# ADSP-2183xW_LPC register map
Vendor: Analog Devices; Series: ADSP-2183xW_LPC; File version: 3.0.3.517
CPU: 
Registers are 32-bit, read-write, reset 0x0 unless marked. A register's access mark holds for its fields unless they carry their own. Offsets are from the block's base; [hi:lo] are bit positions; 'fields as' and 'values as' point back to an identical list.

## DMC0_PHY — 1600MHz DMCPHY (DDR3/DDR3L)
Base 0x31071000
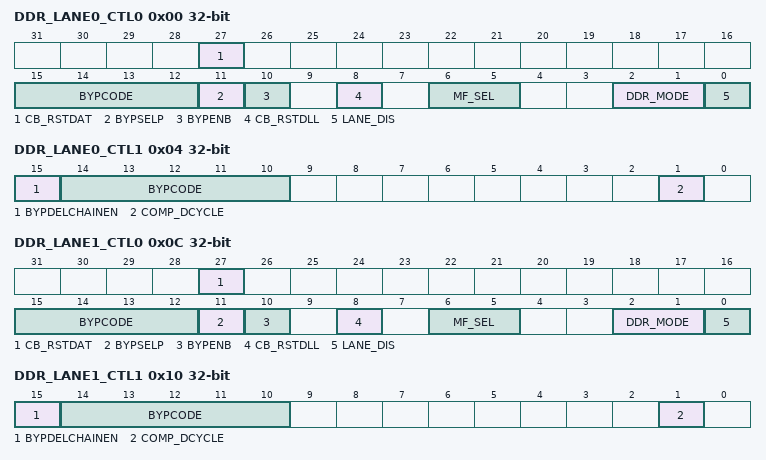
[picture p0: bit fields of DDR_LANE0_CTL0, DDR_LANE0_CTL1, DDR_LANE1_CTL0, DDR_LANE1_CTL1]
0x00 DDR_LANE0_CTL0 — Data Lane 0 Control Register 0
  [27] CB_RSTDAT range 0x00000000..0x00000001 — Reset the Data Pads
  [15:12] BYPCODE range 0x00000000..0x0000000F — Duty Cycle Level
  [11] BYPSELP — Duty Cycle Offset Direction Select
    0=Direction_neg (Negative); 1=Direction_pos (Positive)
  [10] BYPENB — DQS Duty Cycle Offset Adjustment Enable
    0=DQS_Duty_disable (Disable); 1=DQS_duty_enable (Enable)
  [8] CB_RSTDLL range 0x00000000..0x00000001 — Reset the Lane DLL
  [6:5] MF_SEL — SPI Master Frequency Divider Select
    0=DIVBY2 (Divide by 2); 1=DIVBY4 (Divide by 4); 2=DIVBY8 (Divide by 8); 3=DIVBY16 (Divide by 16)
  [2:1] DDR_MODE
    0=DDR3 (DDR3/3L Mode)
  [0] LANE_DIS — Clock Gate Data Lane
    0=ENABLED (Lane is Enabled); 1=DISABLED (Lane is Clock Gated)
0x04 DDR_LANE0_CTL1 — Data Lane 0 Control Register 1
  [15] BYPDELCHAINEN range 0x00000000..0x00000001 — Bypass enable for delay chain controlling extra delay on DATA pins
  [14:10] BYPCODE range 0x00000000..0x0000001F — Bypass Code for extra delay on DATA pins
  [1] COMP_DCYCLE range 0x00000000..0x00000001 — Compute Datacycle
0x0C DDR_LANE1_CTL0 — Data Lane 1 Control Register 0
  fields as DDR_LANE0_CTL0
0x10 DDR_LANE1_CTL1 — Data Lane 1 Control Register 1
  fields as DDR_LANE0_CTL1
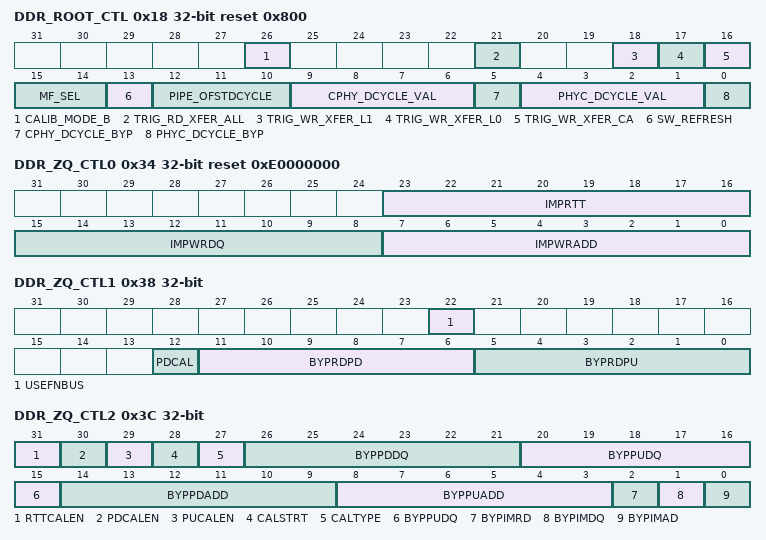
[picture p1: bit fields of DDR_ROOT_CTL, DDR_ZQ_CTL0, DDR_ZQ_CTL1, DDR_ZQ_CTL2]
0x18 DDR_ROOT_CTL reset 0x800 — DDR ROOT Module Control Register
  [26] CALIB_MODE_B range 0x00000000..0x00000001 — Select control bits for CA lane from scratch registers instead of ZQ_CTL registers
  [21] TRIG_RD_XFER_ALL range 0x00000000..0x00000001 — All Lane Read Status
  [18] TRIG_WR_XFER_L1 range 0x00000000..0x00000001 — Write Transfer from Root to Lane1
  [17] TRIG_WR_XFER_L0 range 0x00000000..0x00000001 — Write Transfer from Root to Lane 0
  [16] TRIG_WR_XFER_CA range 0x00000000..0x00000001 — Write Transfer from Root to CA Lane
  [15:14] MF_SEL — SPI Master Frequency Divider Select
    values as DDR_LANE0_CTL0.MF_SEL
  [13] SW_REFRESH range 0x00000000..0x00000001 — Refresh Lane DLL Code
  [12:10] PIPE_OFSTDCYCLE range 0x00000000..0x00000007 — Pipeline offset for PHYC_DATACYCLE
  [9:6] CPHY_DCYCLE_VAL range 0x00000000..0x0000000F — Bypass Value for CPHY_DATACYCLE
  [5] CPHY_DCYCLE_BYP range 0x00000000..0x00000001 — Bypass Enable for CPHY_DATACYCLE
  [4:1] PHYC_DCYCLE_VAL range 0x00000000..0x0000000F — Bypass Value for PHYC_DATACYCLE
  [0] PHYC_DCYCLE_BYP range 0x00000000..0x00000001 — Bypass Enable for PHYC_DATACYCLE
0x34 DDR_ZQ_CTL0 reset 0xE0000000 — DDR Calibration Control Register 0
  [23:16] IMPRTT range 0x00000000..0x000000FF — Data/DQS ODT
  [15:8] IMPWRDQ range 0x00000000..0x000000FF — Data/DQS/DM/CLK Drive Strength
  [7:0] IMPWRADD range 0x00000000..0x000000FF — Address/Command Drive Strength
0x38 DDR_ZQ_CTL1 — DDR Calibration Control Register 1
  [22] USEFNBUS range 0x00000000..0x00000001 — BSCAN Mode
  [12] PDCAL range 0x00000000..0x00000001 — Calibration Pad Power Down
  [11:6] BYPRDPD range 0x00000000..0x0000003F — Pull-down Termination Bypass Code
  [5:0] BYPRDPU range 0x00000000..0x0000003F — Pull-up Termination Bypass Code
0x3C DDR_ZQ_CTL2 — DDR Calibration Control Register 2
  [31] RTTCALEN range 0x00000000..0x00000001 — Pad ODT Strength Calibration Enable
  [30] PDCALEN range 0x00000000..0x00000001 — Driver Pull-down Strength Calibration Enable
  [29] PUCALEN range 0x00000000..0x00000001 — Driver Pull-up Strength Calibration Enable
  [28] CALSTRT range 0x00000000..0x00000001 — New Impedance Calibration Enable
  [27] CALTYPE range 0x00000000..0x00000001 — Calibration Type
  [26:21] BYPPDDQ range 0x00000000..0x0000003F — Bypass Code for DQ,DQS,CLK,DM Pull-down Driver Code
  [20:15] BYPPUDQ range 0x00000000..0x0000003F — Bypass Code for DQ,DQS,CLK,DM Pull-up Code
  [14:9] BYPPDADD range 0x00000000..0x0000003F — Address/Command Bypass Pull-down Code
  [8:3] BYPPUADD range 0x00000000..0x0000003F — Address/Command Bypass Pull-up Codes
  [2] BYPIMRD range 0x00000000..0x00000001 — Bypass Termination Code Enable
  [1] BYPIMDQ range 0x00000000..0x00000001 — DQ/DQS/CLK/DM Bypass Driver Code Enable
  [0] BYPIMAD range 0x00000000..0x00000001 — Address/Command Bypass Code Enable
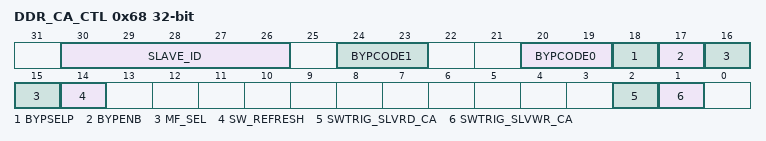
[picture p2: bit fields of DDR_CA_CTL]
0x68 DDR_CA_CTL — DDR CA Lane Control Register
  [30:26] SLAVE_ID range 0x00000000..0x0000001F — SW Completer Read/Write Completer ID
  [24:23] BYPCODE1 range 0x00000000..0x00000003 — Duty Cycle Level Select
  [20:19] BYPCODE0 range 0x00000000..0x00000003 — Duty Cycle Level Select
  [18] BYPSELP — Duty Cycle Offset Direction Select
    0=Direction_neg (Negative); 1=Direction_pos (Positive)
  [17] BYPENB — CLK Duty Cycle Offset Adjustment Enable
    0=Disable; 1=Enable
  [16:15] MF_SEL — SPI Master Frequency Divider Select
    values as DDR_LANE0_CTL0.MF_SEL
  [14] SW_REFRESH range 0x00000000..0x00000001 — Refresh Lane DLL Code
  [2] SWTRIG_SLVRD_CA range 0x00000000..0x00000001 — Software Trigger Completer Read
  [1] SWTRIG_SLVWR_CA range 0x00000000..0x00000001 — Software Trigger Completer Write
0x74 DDR_SCRATCH_2 — Scratch Register 2
  [31:0] CALIB_MODE_B_CTL range 0x00000000..0xFFFFFFFF — Control bits for CA lane Completers when CALIB_MODE_B is HIGH
0x78 DDR_SCRATCH_3 — Scratch Register 3
  fields as DDR_SCRATCH_2
0x7C DDR_SCRATCH_4 — Scratch Register 4
  [31:0] WR_LVL_CODE_L0 range 0x00000000..0xFFFFFFFF — Write leveling code read back from Lane0
0x80 DDR_SCRATCH_5 — Scratch Register 5
  [31:0] WR_LVL_CODE_L1 range 0x00000000..0xFFFFFFFF — Write leveling code read back from Lane1
0x84 DDR_SCRATCH_6 — Scratch Register 6
  [31:0] CALIB_CODE_STAT range 0x00000000..0xFFFFFFFF — Calibration code read back from CALIB PAD Completer
0x88 DDR_SCRATCH_7 — Scratch Register 7
  fields as DDR_SCRATCH_6
